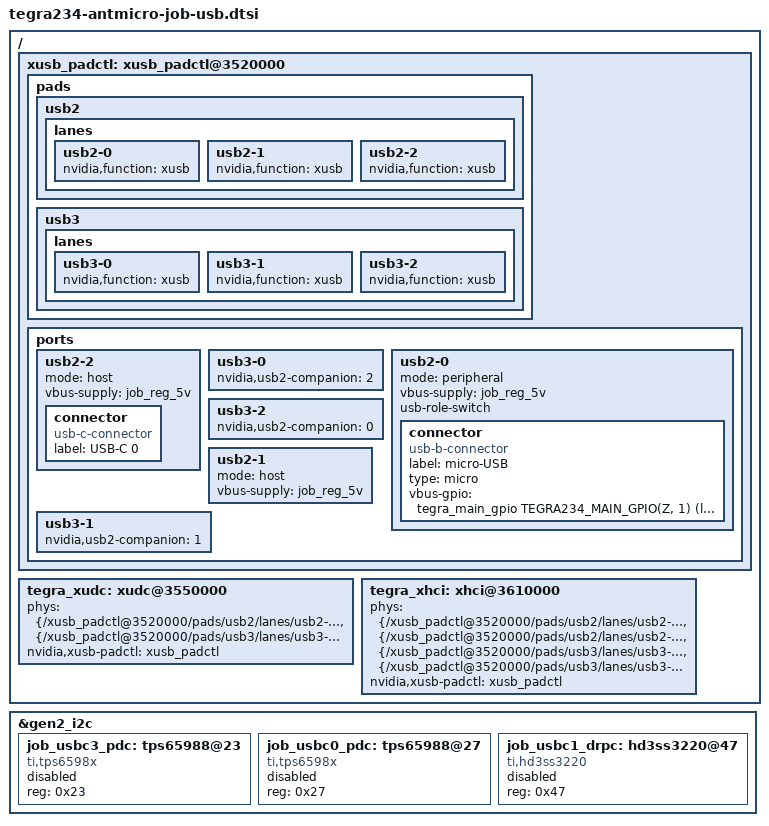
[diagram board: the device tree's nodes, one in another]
/*
 * Copyright (c) 2023 Antmicro <www.antmicro.com>
 *
 * This program is free software; you can redistribute it and/or modify
 * it under the terms of the GNU General Public License as published by
 * the Free Software Foundation; version 2 of the License.
 *
 * This program is distributed in the hope that it will be useful, but WITHOUT
 * ANY WARRANTY; without even the implied warranty of MERCHANTABILITY or
 * FITNESS FOR A PARTICULAR PURPOSE.  See the GNU General Public License for
 * more details.
 */


/*
 * Placeholders for USB PD and DRP controllers on SYS I2C bus
 * (not implemented)
 */
&gen2_i2c {
	/*
	 * TPS65988 dual-port USB-C Power Delivery controller
	 * port1 is USBC3 (J3) @ i2c_addr=h23
	 * port2 is USBC0 (J4) @ i2c_addr=h27
	 */
	job_usbc3_pdc: tps65988@23 {
		compatible = "ti,tps6598x";
		status = "disabled";
		reg = <0x23>;
	};

	job_usbc0_pdc: tps65988@27 {
		compatible = "ti,tps6598x";
		status = "disabled";
		reg = <0x27>;
	};

	/*
	 * HD3SS3220 dual role port controller for USBC1 port
	 * NOTE: this is just a DRD/DRP without Power Delivery
	 */
	job_usbc1_drpc: hd3ss3220@47 {
		compatible = "ti,hd3ss3220";
		status = "disabled";
		reg = <0x47>;
	};
};

/ {
	xusb_padctl: xusb_padctl@3520000 {
		/*
		 * See Documentation/devicetree/bindings/phy/
		 * nvidia,tegra124-xusb-padctl.txt for reference
		 */
		status = "okay";
		pads {
			usb2 {
				lanes {
					usb2-0 {
						nvidia,function = "xusb";
						status = "okay";
					};
					usb2-1 {
						nvidia,function = "xusb";
						status = "okay";
					};
					usb2-2 {
						nvidia,function = "xusb";
						status = "okay";
					};
				};
			};
			usb3 {
				lanes {
					usb3-0 {
						nvidia,function = "xusb";
						status = "okay";
					};
					usb3-1 {
						nvidia,function = "xusb";
						status = "okay";
					};
					usb3-2 {
						nvidia,function = "xusb";
						status = "okay";
					};
				};
			};
		};

		ports {
			/* USB-C 0 */
			usb2-2 {
				mode = "host";
				/* Delegate switching to HW (consider VBUS always on) */
				vbus-supply = <&job_reg_5v>;
				status = "okay";
				connector {
					compatible = "usb-c-connector";
 					label = "USB-C 0";
 				};
			};
			usb3-0 {
				nvidia,usb2-companion = <2>;
				status = "okay";
			};

			/* USB-C 1 (also functions as a Jetson recovery port) */
			usb2-0 {
				mode = "peripheral";
				status = "okay";
				/* Delegate switching to HW (consider VBUS always on) */
				vbus-supply = <&job_reg_5v>;
				usb-role-switch;
				connector {
					compatible = "usb-b-connector", "gpio-usb-b-connector";
 					label = "micro-USB";
 					type = "micro";
 					vbus-gpio = <&tegra_main_gpio TEGRA234_MAIN_GPIO(Z, 1) GPIO_ACTIVE_LOW>;
 				};
			};
			usb3-2 {
				nvidia,usb2-companion = <0>;
				status = "okay";
			};

			/* USB on M.2 & extension connector */
			usb2-1 {
				mode = "host";
				/* VBUS is always on */
				vbus-supply = <&job_reg_5v>;
				status = "okay";
			};
			usb3-1 {
				nvidia,usb2-companion = <1>;
				status = "okay";
			};
		};
	};

	/* USB Device controller */
	tegra_xudc: xudc@3550000 {
		status = "okay";
		phys = <&{/xusb_padctl@3520000/pads/usb2/lanes/usb2-0}>,
			<&{/xusb_padctl@3520000/pads/usb3/lanes/usb3-2}>;
		phy-names = "usb2-0", "usb3-2";
		nvidia,xusb-padctl = <&xusb_padctl>;
	};

	/* USB Host controller */
	tegra_xhci: xhci@3610000 {
		status = "okay";
		phys = <&{/xusb_padctl@3520000/pads/usb2/lanes/usb2-1}>,
			<&{/xusb_padctl@3520000/pads/usb2/lanes/usb2-2}>,
			<&{/xusb_padctl@3520000/pads/usb3/lanes/usb3-0}>,
			<&{/xusb_padctl@3520000/pads/usb3/lanes/usb3-1}>;
		phy-names = "usb2-1", "usb2-2", "usb3-0", "usb3-1";
		nvidia,xusb-padctl = <&xusb_padctl>;
	};
};
